# SDTI register map
Vendor: Texas Instruments
Peripheral module from a debugger description file (folder omap36xx).
Registers are 32-bit, read-only, reset 0x0 unless marked. A register's access mark holds for its fields unless they carry their own. Offsets are as the file gives them; lines under a group give offsets from that group; [hi:lo] are bit positions; {n}, {i} and the like mark numbered series; 'fields as' and 'values as' point back to an identical list; <NAME> marks a mode.

## SDTI
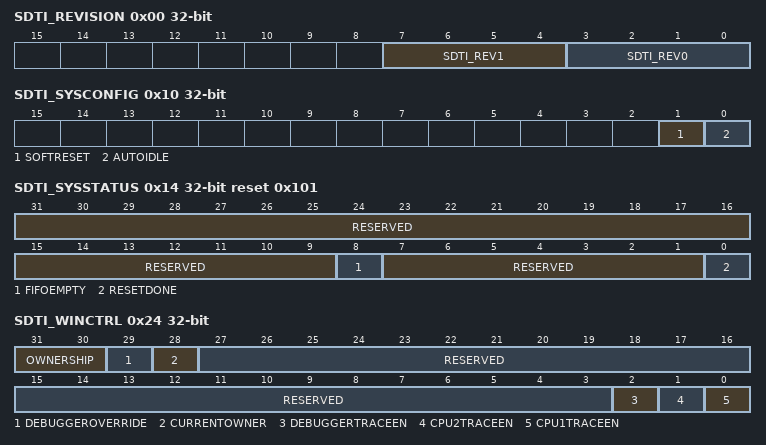
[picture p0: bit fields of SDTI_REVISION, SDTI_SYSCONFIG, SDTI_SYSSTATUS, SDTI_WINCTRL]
0x00 SDTI_REVISION (reset mask 0xFFFFFF00) — SDTI Identification Register
  [7:4] SDTI_REV1 — High Part of Revision Number of current SDTI module fixed by hardware: it indicates major change.
  [3:0] SDTI_REV0 — Low Part of Revision Number of current SDTI module fixed by hardware: it indicates minor change.
0x10 SDTI_SYSCONFIG access per field — This register allows controlling various parameters of the OCP interface.Software reset have the same effect as hardware (power on) reset.This register is excluded from erroneous application access lock protection in order to allow standard soft reset OCP write access.
  [1] SOFTRESET rw — Read returns 0 / Write 1 to trigger SDTI module reset.
  [0] AUTOIDLE rw — Internal OCP gating strategyOCP clock is free-runningAutomatic OCP clock gating strategy is appliedbased on OCP interface activity
0x14 SDTI_SYSSTATUS reset 0x101 — This register provides status information about the module, excluding the interrupt status information.
  [31:9] RESERVED — RFU for module specific status information
  [8] FIFOEMPTY — SDTI FIFO not Empty (something to export)SDTI FIFO EmptyWrite access has no effect.
  [7:1] RESERVED — RFU for OCP socket status information.
    0=RESERVED_0_r (Internal module reset in on-going); 1=RESERVED_1_r (Reset completed)
  [0] RESETDONE — Internal Module reset monitoringInternal reset is on-goingReset completed
0x24 SDTI_WINCTRL access per field — Window control register.
  [31:30] OWNERSHIP rw — Read to get current ownership status. The claim status encoding is (0=Available, 1=Claimed, 2=Enabled, 3=Reserved)Send command to modify ownership state. See Table 13Note: (1) A successful command would cause these bit values to reflect the new state.
  [29] DEBUGGEROVERRIDE rw — Reading from the DebuggerOverride bit returns a 1This qualifier bit is used with the debugger's CLAIM request. The DebuggerOverride bit shall not be latched.When written with DebuggerOverride=1, a claim request by the debugger shall be granted regardless of current ownership status of the unit.When written with DebuggerOverride=0, the claim request shall be granted only if the unit is available.
  [28] CURRENTOWNER rw — This value reflects the SDTI ownership when the register is in a non-Available state.0=Debugger owns resource.1=Application owns resource
  [27:3] RESERVED ro — RFU
  [2] DEBUGGERTRACEEN rw — 0 Debugger writes to address matching window doesn't generate messages./1 Debugger writes to address matching window will generate messages
  [1] CPU2TRACEEN rw — 0 Window disabled, no message generation/ 1Window enabled
  [0] CPU1TRACEEN rw — 0 Window disabled, no message generation/ 1Window enabled
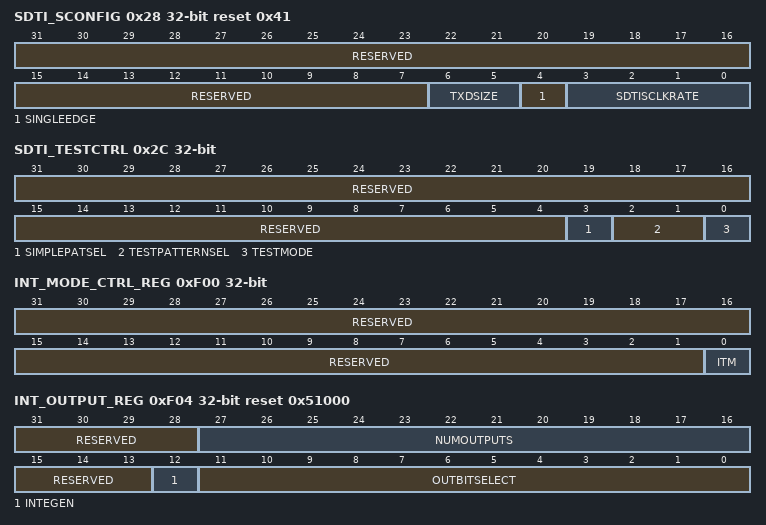
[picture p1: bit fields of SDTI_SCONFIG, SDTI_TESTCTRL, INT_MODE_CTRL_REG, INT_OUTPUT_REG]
0x28 SDTI_SCONFIG rw reset 0x41 — SDTI Serial configuration register.
  [31:7] RESERVED — RFU
  [6:5] TXDSIZE — 00 1 bit TXD size/01 2-bit TXD size/10 4-bit TXD size/11 Reserved. (if set, interface will behave as 4-bit size)
  [4] SINGLEEDGE — 0 Dual -edge operation mode/1 Single - edge operation mode
  [3:0] SDTISCLKRATE — 0x0: Division by 10x1: Division by 10x2: Division by 20x3: Division by 30x4: Division by 40x5: Division by 50x6: Division by 60x7: Division by 70x8: Division by 80x9: Division by 90xA: Division by 10Others: Division by 1
0x2C SDTI_TESTCTRL access per field
  [31:4] RESERVED ro — RFU
  [3] SIMPLEPATSEL rw — 0 - simple pattern A1 - simple pattern F
  [2:1] TESTPATTERNSEL rw — 00 - Simple pattern01 - Walking ones pattern10 - Ramp generation (incremental counter)11 - Pseudo random
  [0] TESTMODE rw — 0 - SDTI serial interface exports trace messages (functional mode)1 - SDTI serial interface exports selected test patterns (test mode)
0xF00 INT_MODE_CTRL_REG access per field
  [31:1] RESERVED ro — RFU
  [0] ITM rw — Functional ModeWhen ITM=1, the SDTI is in Integration Test Mode.
0xF04 INT_OUTPUT_REG access per field reset 0x51000 — This register allows the software to set any one of the output terminal to a high when the ITM signal is high. This register can be used to establish integration connectivity and topology. Refer to the Appendix, 7.1 SDTI Entity Table 17 to determine the OutBit Select number for each terminal.
  [31:28] RESERVED ro — RFU
  [27:16] NUMOUTPUTS ro — This field shall indicate the number of output terminals on the component
  [15:13] RESERVED ro — RFU
  [12] INTEGEN rw — When IntegEn=1, the integration output is set to 1
  [11:0] OUTBITSELECT rw — This field shall selects the output bit to set high
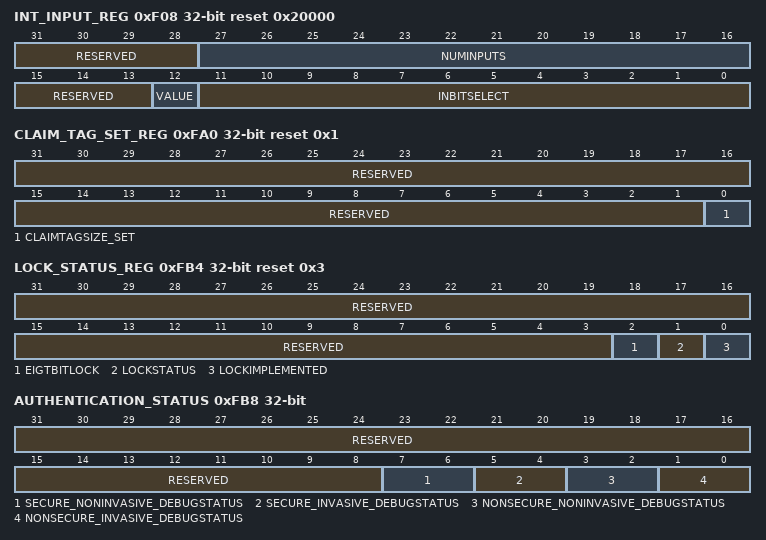
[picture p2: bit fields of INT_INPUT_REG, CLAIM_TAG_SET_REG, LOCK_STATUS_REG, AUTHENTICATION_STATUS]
0xF08 INT_INPUT_REG access per field reset 0x20000 — This register allows the software to read any of the input terminals when the ITM signal is high. This register can be used to establish integration connectivity and topology. Refer to the Appendix, 7.1 SDTI Entity Table 17 to determine the InBit Select number for each terminal.
  [31:28] RESERVED ro — RFU
  [27:16] NUMINPUTS ro — This field shall indicate the number of input terminals on the component
  [15:13] RESERVED ro — RFU
  [12] VALUE ro — This field shall selects the input bit to read
  [11:0] INBITSELECT rw — This field shall selects the input bit to read
0xFA0 CLAIM_TAG_SET_REG access per field reset 0x1 — The Claim Tag Set register is included for CoreSight compliance. Normally the lower 4 bits are used for claiming and releasing debug components, but SDTI implements a more sophisticated Claim mechanism. These bits can be used for software semaphores to help manage the debug resources, although the claim and enable mechanism of the SDTI resources must still be used. Writing a 1 to one of the set bits will cause the corresponding bit in the Claim Tag Value word to go high.
  [31:1] RESERVED ro — RFU
  [0] CLAIMTAGSIZE_SET rw — When read, this field shall indicates the modules supports a 1-bit claim tagWriting a 1 shall: sets the specified Claim Tag Value bit. Writing a 0 shall have no effect.
0xFA4 CLAIM_TAG_CLEAR_REG access per field — These bits can be used for software semaphores to help manage the debug resources. Writing a 1 to one of the clear bits will cause the corresponding bit in the Claim Tag Value word to go low. Reading this register returns the Claim Tag Value
  [0] CLAINTAGVALUE_CLEAR rw — Reading from this field shall return the Claim Tag ValueWriting a 1 shall: clear the specified Claim Tag Value bit. Writing a 0 shall have no effect.
0xFB0 LOCK_ACCESS_REG wo — NoteThis 32-bit write only register is used to lockout errant accesses by application software. When written with a value of 0xC5ACCE55, application writes to the other registers within SDTI are enabled. Any other value shall inhibit application writes (write to Lock Access Register is always enabled). Inhibited application writes shall return an error response. Debugger accesses (PIMREQDEBUG = 1) are not affected by the Lock Access Register. This register is reset to zero (locked) when POR occurs. register is excluded from lock access scheme.
  [31:0] LOCK_UNLOCK_KEY — Unlock Key: 0xC5ACCE55
0xFB4 LOCK_STATUS_REG reset 0x3 — Lock status register - registers provide a mechanism for blocking write access to the SDTI registers
  [31:3] RESERVED — RFU
  [2] EIGTBITLOCK — 0 indicates a 32-bit Lock Access Register1 indicates an 8-bit Lock Access Register.
  [1] LOCKSTATUS — 0 indicates unlocked condition1 indicates a locked condition.
  [0] LOCKIMPLEMENTED — 0 shall indicate no lock exists.1 indicates a locking mechanism exists,
0xFB8 AUTHENTICATION_STATUS — Authentication status registar
  [31:8] RESERVED — RFU
  [7:6] SECURE_NONINVASIVE_DEBUGSTATUS — The Secure Non-Invasive Debug Status shall return 00 (functionality not implemented)
  [5:4] SECURE_INVASIVE_DEBUGSTATUS — The Secure Invasive Debug Status shall return 00. (functionality not implemented)
  [3:2] NONSECURE_NONINVASIVE_DEBUGSTATUS — The Non-Secure Non-Invasive Debug Status shall return 00 (functionality not implemented)
  [1:0] NONSECURE_INVASIVE_DEBUGSTATUS — The Non-Secure Invasive Debug Status shall return 00.(functionality not implemented)
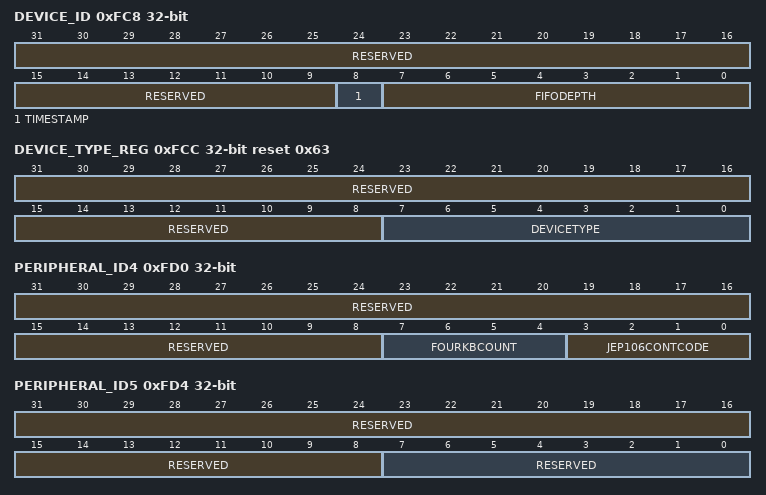
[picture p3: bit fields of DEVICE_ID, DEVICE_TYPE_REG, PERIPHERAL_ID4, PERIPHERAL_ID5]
0xFC8 DEVICE_ID — Device identification register.The Device ID register is capability register and is implementation defined according to the CoreSight specification
  [31:9] RESERVED — RFU
  [8] TIMESTAMP — 0 - TimeStamping feature not supported in SDTI1 - TimeStamping present in SDTI
  [7:0] FIFODEPTH — SDTI FFIFO depth
0xFCC DEVICE_TYPE_REG reset 0x63 — Device type register
  [31:8] RESERVED — RFU
  [7:0] DEVICETYPE — The device type shall return 0x63. Enables devices to be identified as to their CoreSight Class.
0xFD0 PERIPHERAL_ID4 — All Peripheral ID registers are implemented as 8-bit registers with the upper 24 bits returning a value of zero.
  [31:8] RESERVED — RFU
  [7:4] FOURKBCOUNT — 4KB Count
  [3:0] JEP106CONTCODE — JEP106 Continuation Code
0xFD4 PERIPHERAL_ID5 access per field — All Peripheral ID registers are implemented as 8-bit registers with the upper 24 bits returning a value of zero.
  [31:8] RESERVED rw — RFU
  [7:0] RESERVED ro — RFU
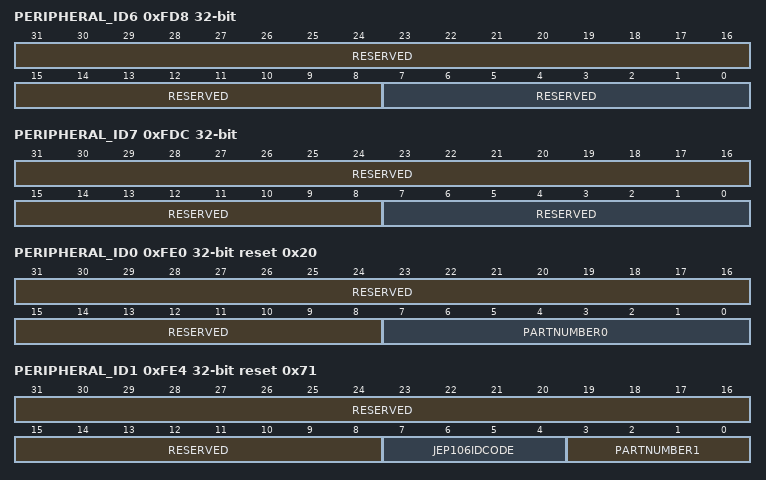
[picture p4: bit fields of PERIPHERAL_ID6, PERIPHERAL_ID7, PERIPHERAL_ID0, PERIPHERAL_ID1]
0xFD8 PERIPHERAL_ID6 — All Peripheral ID registers are implemented as 8-bit registers with the upper 24 bits returning a value of zero.
  [31:8] RESERVED — RFU
  [7:0] RESERVED — RFU
0xFDC PERIPHERAL_ID7 — All Peripheral ID registers are implemented as 8-bit registers with the upper 24 bits returning a value of zero.
  [31:8] RESERVED — RFU
  [7:0] RESERVED — RFU
0xFE0 PERIPHERAL_ID0 reset 0x20 — All Peripheral ID registers are implemented as 8-bit registers with the upper 24 bits returning a value of zero.
  [31:8] RESERVED — RFU
  [7:0] PARTNUMBER0 — 0x20 Part Number 0 (Middle and Lower BCD value of Device Number)
0xFE4 PERIPHERAL_ID1 reset 0x71 — All Peripheral ID registers are implemented as 8-bit registers with the upper 24 bits returning a value of zero.
  [31:8] RESERVED — RFU
  [7:4] JEP106IDCODE — JEP106 identity code [3:0]
  [3:0] PARTNUMBER1 — Part number 1 (upper BCD value of device number)
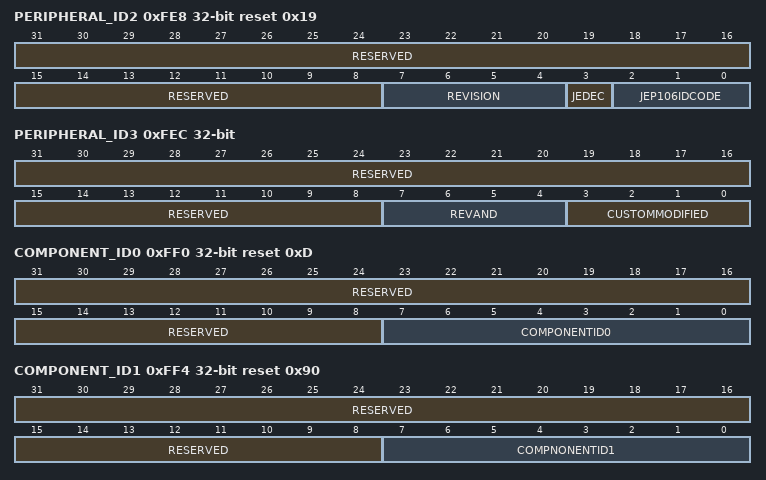
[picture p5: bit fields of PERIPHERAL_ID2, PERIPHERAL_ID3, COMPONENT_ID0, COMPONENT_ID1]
0xFE8 PERIPHERAL_ID2 reset 0x19 — All Peripheral ID registers are implemented as 8-bit registers with the upper 24 bits returning a value of zero.
  [31:8] RESERVED — RFU
  [7:4] REVISION — Revision number of peripheral.Major revision from OCP version register.
  [3] JEDEC — Indicates that a JEDEC assigned value is used.
  [2:0] JEP106IDCODE — JEP106 identity code [6:4]
0xFEC PERIPHERAL_ID3 — All Peripheral ID registers are implemented as 8-bit registers with the upper 24 bits returning a value of zero.
  [31:8] RESERVED — RFU
  [7:4] REVAND — RevAnd (at top level)
  [3:0] CUSTOMMODIFIED — Customer Modified
0xFF0 COMPONENT_ID0 reset 0xD — All Component ID registers are implemented as 8-bit registers with the upper 24 bits returning a value of zero. These registers are used to indicate to software the existence of a peripheral. Software will read the last four locations in each 4K block to determine if a Coresight Peripheral exists.
  [31:8] RESERVED — RFU
  [7:0] COMPONENTID0 — This register shall return Preamble value 0x0D
0xFF4 COMPONENT_ID1 reset 0x90 — All Component ID registers are implemented as 8-bit registers with the upper 24 bits returning a value of zero. These registers are used to indicate to software the existence of a peripheral. Software will read the last four locations in each 4K block to determine if a Coresight Peripheral exists.
  [31:8] RESERVED — RFU
  [7:0] COMPNONENTID1 — This register shall return Preamble value 0x90
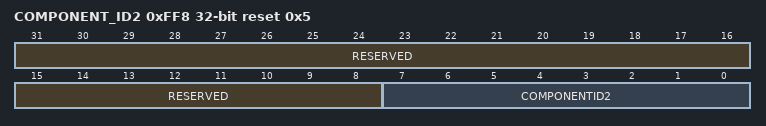
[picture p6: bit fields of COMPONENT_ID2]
0xFF8 COMPONENT_ID2 reset 0x5 — All Component ID registers are implemented as 8-bit registers with the upper 24 bits returning a value of zero. These registers are used to indicate to software the existence of a peripheral. Software will read the last four locations in each 4K block to determine if a Coresight Peripheral exists.
  [31:8] RESERVED — RFU
  [7:0] COMPONENTID2 — This register shall return Preamble value 0x05
0xFFC COMPONENT_ID3 reset 0xB1 — All Component ID registers are implemented as 8-bit registers with the upper 24 bits returning a value of zero. These registers are used to indicate to software the existence of a peripheral. Software will read the last four locations in each 4K block to determine if a Coresight Peripheral exists.
  [7:0] COMPONENTID3 — This register shall return Preamble value 0xB1
